# R7FA4L1BD register map
Vendor: Renesas Electronics Corporation; Series: RA4; File version: 0.90.02
CPU: CM33 r0p4, little endian, MPU, FPU, VTOR, 4 interrupt priority bits, 96 interrupts
Registers are 32-bit, read-write, reset 0x0 unless marked. A register's access mark holds for its fields unless they carry their own. Offsets are from the block's base; [hi:lo] are bit positions; {n}, {i} and the like mark numbered series; 'fields as' and 'values as' point back to an identical list; <NAME> marks a mode.

## CTSU — Capacitive Touch Sensing Unit
Base 0x400D0000
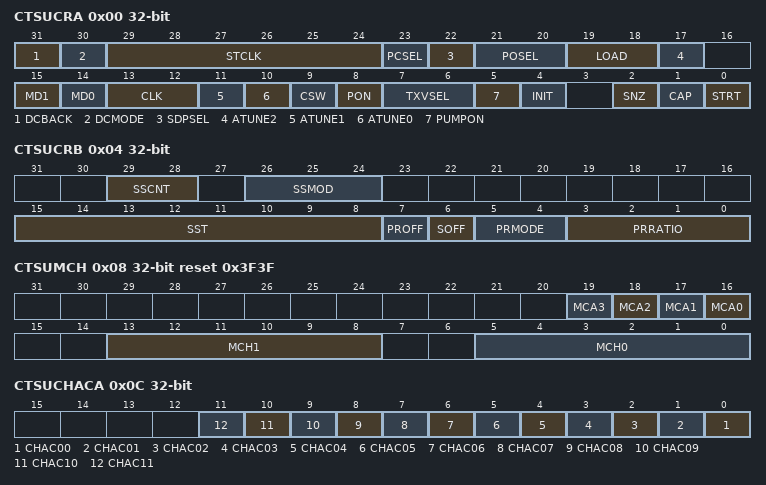
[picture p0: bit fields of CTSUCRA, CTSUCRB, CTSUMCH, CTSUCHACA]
0x00 CTSUCRA — CTSU Control Register A
  [31] DCBACK — CTSU Current Measurement Feedback Select
    0=TSCAP pin is selected; 1=Measurement pin is selected. It is recommended in the current measurement mode.
  [30] DCMODE — CTSU Current Measurement Mode Select
    0=Electrostatic capacitance measurement mode; 1=Current measurement mode
  [29:24] STCLK — CTSU STCLK Select
  [23] PCSEL — CTSU Boost Circuit Clock Select
    0=Sensor drive pulse divided by 2; 1=STCLK
  [22] SDPSEL — CTSU Sensor Drive Pulse Select
    0=Random pulse; 1=Normal pulse using the sensor unit clock
  [21:20] POSEL — CTSU Non-Measured Channel Output Select
    0=Output low; 1=Hi-Z; 2=Output low (uses power supply selected by TXVSEL[1:0] bits); 3=Output a pulse in phase with the transmit channel
  [19:18] LOAD — CTSU Load Control During Measurement
    0=2.5 µA constant current load; 1=No load; 2=20 µA constant current load and overcurrent detector disabled; 3=Resistance load for calibration. To set LOAD[1:0] bits to resistance load for calibration, set these bits to 01b before they are set to 11b.
  [17] ATUNE2 — CTSU Current Range Adjustment
    0=80 µA when ATUNE1 = 0 40 µA when ATUNE1 = 1; 1=20 µA when ATUNE1 = 0 160 µA when ATUNE1 = 1
  [15] MD1 — CTSU Measurement Mode Select 1
    0=One-time measurement (self-capacitance method); 1=Two times measurement (mutual capacitance method)
  [14] MD0 — CTSU Measurement Mode Select 0
    0=Single scan mode; 1=Multi-scan mode
  [13:12] CLK — CTSU Operating Clock Select
    0=PCLKB; 1=PCLKB/2 (PCLKB divided by 2); 2=PCLKB/4 (PCLKB divided by 4); 3=PCLKB/8 (PCLKB divided by 8)
  [11] ATUNE1 — CTSU Current Range Adjustment
    0=80 µA when ATUNE2 = 0 20 µA when ATUNE2 = 1; 1=40 µA when ATUNE2 = 0 160 µA when ATUNE2 = 1
  [10] ATUNE0 — CTSU Power Supply Operating Mode Setting
    0=VCC ≥ 2.4 V: Normal voltage operating mode VCC < 2.4 V: Setting prohibited; 1=Low-voltage operating mode
  [9] CSW — TSCAP Pin Enable
    0=Disable; 1=Enable
  [8] PON — CTSU Power On Control
    0=Power off the CTSU; 1=Power on the CTSU
  [7:6] TXVSEL — CTSU Transmission Power Supply Selection
    0=Selecting VCC as the power supply for the transmit pins of mutual capacitance method; 1=Selecting VCC as the power supply for the transmit pins of the mutual capacitance method. In addition, noise is reduced during GPIO operation. (Recommended); 2=Select VCC as the power source for the transmitter pins used as the active shield; 3=Setting prohibited
  [5] PUMPON — CTSU Boost Circuit Control
    0=Boost circuit off; 1=Boost circuit on
  [4] INIT wo — CTSU Control Block Initialization
  [2] SNZ — CTSU Wait State Power-Saving Enable
    0=Disable power-saving function during wait state; 1=Enable power-saving function during wait state
  [1] CAP — CTSU Measurement Operation Start Trigger Select
    0=Software trigger; 1=External trigger
  [0] STRT — CTSU Measurement Operation Start
    0=Stop measurement operation; 1=Start measurement operation
0x00 CTSUCRAL 16-bit (alternate view of CTSUCRA) — CTSU Control Register A
0x00 CTSUCR0 8-bit (alternate view of CTSUCRA) — CTSU Control Register A
0x01 CTSUCR1 8-bit (alternate view of CTSUCRA) — CTSU Control Register A
0x02 CTSUCR2 8-bit (alternate view of CTSUCRAH) — CTSU Control Register A
0x03 CTSUCR3 8-bit (alternate view of CTSUCRA) — CTSU Control Register A
0x04 CTSUCRB — CTSU Control Register B
  [29:28] SSCNT — SUCLK Spread-Spectrum Control
    0=CTSUTRIMA.SUADJD[7:0] + 0x00; 1=CTSUTRIMA.SUADJD[7:0] + 0x20; 2=CTSUTRIMA.SUADJD[7:0] + 0x40; 3=CTSUTRIMA.SUADJD[7:0] + 0x60
  [26:24] SSMOD — SUCLK Spread-Spectrum Mode Select
    0=256 cycles; 1=384 cycles; 2=512 cycles; 3=1024 cycles; 7=No spread-spectrum; other=Others (Settings are prohibited)
  [15:8] SST — Sensor Stabilization Wait Time Setting
  [7] PROFF — Pseudo-Random Number Off
    0=Perform pseudo-random number control; 1=Do not perform pseudo-random number control
  [6] SOFF — Jitter Injection Off Setting
    0=Inject jitter; 1=Do not inject jitter
  [5:4] PRMODE — Pseudo-Random Number Generation Cycle Setting
    0=255 cycles; 1=63 cycles; 2=31 cycles; 3=3 cycles
  [3:0] PRRATIO — Phase Shift Frequency Setting
0x04 CTSUCRBL 16-bit (alternate view of CTSUCRB) — CTSU Control Register B
0x04 CTSUSDPRS 8-bit (alternate view of CTSUCRB) — CTSU Control Register B
0x05 CTSUSST 8-bit (alternate view of CTSUCRB) — CTSU Control Register B
0x06 CTSUCRBH 16-bit (alternate view of CTSUCRB) — CTSU Control Register B
0x07 CTSUDCLKC 8-bit (alternate view of CTSUCRB) — CTSU Control Register B
0x08 CTSUMCH reset 0x3F3F — CTSU Measurement Channel Register
  [n+16] MCA{n} (n=0..3) — Multiple Clocks Control
    0=Disable; 1=Enable
  [13:8] MCH1 — CTSU Measurement Channel 1
    {v}=TS{v:02} (v=0..11); 63=Measurement is being stopped
  [5:0] MCH0 — CTSU Measurement Channel 0
    {v}=TS{v:02} (v=0..11); 63=Measurement is being stopped
0x08 CTSUMCHL 16-bit reset 0x3F3F (alternate view of CTSUMCH) — CTSU Measurement Channel Register
0x08 CTSUMCH0 8-bit reset 0x3F (alternate view of CTSUMCH) — CTSU Measurement Channel Register
0x09 CTSUMCH1 8-bit reset 0x3F (alternate view of CTSUMCH) — CTSU Measurement Channel Register
0x0A CTSUMCHH 16-bit (alternate view of CTSUMCH) — CTSU Measurement Channel Register
0x0A CTSUMFAF 8-bit (alternate view of CTSUMCHH) — CTSU Measurement Channel Register
0x0C CTSUCHACA — CTSU Channel Enable Control Register A
  [all] fields
    0=Do not measure; 1=Measure
  [n] CHAC{n:02} (n=0..11) — CTSU Channel Enable Control A
0x0C CTSUCHACAL 16-bit (alternate view of CTSUCHACA) — CTSU Channel Enable Control Register A
0x0C CTSUCHAC0 8-bit (alternate view of CTSUCHACA) — CTSU Channel Enable Control Register A
0x0D CTSUCHAC1 8-bit (alternate view of CTSUCHACA) — CTSU Channel Enable Control Register A
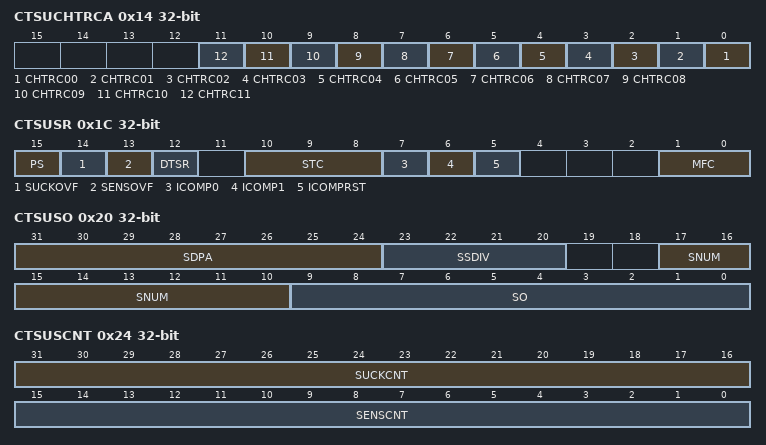
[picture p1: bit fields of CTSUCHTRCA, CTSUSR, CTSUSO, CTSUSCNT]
0x14 CTSUCHTRCA — CTSU Channel Transmit/Receive Control Register A
  [all] fields
    0=Reception; 1=Transmission
  [n] CHTRC{n:02} (n=0..11) — CTSU Channel Transmit/Receive Control A
0x14 CTSUCHTRCAL 16-bit (alternate view of CTSUCHTRCA) — CTSU Channel Transmit/Receive Control Register A
0x14 CTSUCHTRC0 8-bit (alternate view of CTSUCHTRCA) — CTSU Channel Transmit/Receive Control Register A
0x15 CTSUCHTRC1 8-bit (alternate view of CTSUCHTRCA) — CTSU Channel Transmit/Receive Control Register A
0x1C CTSUSR — CTSU Status Register
  [15] PS ro — CTSU Mutual Capacitance Status Flag
    0=First measurement; 1=Second measurement
  [14] SUCKOVF — CTSU SUCLK Counter Overflow Flag
    0=No overflow occurred; 1=Overflow occurred
  [13] SENSOVF — CTSU Sensor Counter Overflow Flag
    0=No overflow occurred; 1=Overflow occurred
  [12] DTSR ro — CTSU Data Transfer Status Flag
    0=Read; 1=Not read
  [10:8] STC ro — CTSU Measurement Status Counter
    {v}=Status {v} (v=0..5)
  [7] ICOMP0 ro — Over-Voltage Detection Flag
    0=Normal; 1=Over-voltage is detected
  [6] ICOMP1 ro — CTSU Sense Current Error Monitor
    0=Normal sensor current; 1=Abnormal sensor current
  [5] ICOMPRST wo — CTSU ICOMP0 and ICOMP1 Flags Reset
  [1:0] MFC — CTSU Multi-Clock Counter
    {v}=Multi-clock {v} (v=0..3)
0x1C CTSUSRL 16-bit (alternate view of CTSUSR) — CTSU Status Register
0x1C CTSUSR0 8-bit (alternate view of CTSUSR) — CTSU Status Register
0x1D CTSUST 8-bit (alternate view of CTSUSR) — CTSU Status Register
0x1E CTSUSRH 16-bit (alternate view of CTSUSR) — CTSU Status Register
0x1E CTSUSR2 8-bit (alternate view of CTSUSRH) — CTSU Status Register
0x20 CTSUSO — CTSU Sensor Offset Register
  [31:24] SDPA — CTSU Base Clock Setting
  [23:20] SSDIV — Spread Spectrum Frequency
  [17:10] SNUM — CTSU Measurement Count Setting
  [9:0] SO — CTSU Sensor Offset Adjustment
0x20 CTSUSO0 16-bit (alternate view of CTSUSO) — CTSU Sensor Offset Register
0x22 CTSUSO1 16-bit (alternate view of CTSUSO) — CTSU Sensor Offset Register
0x24 CTSUSCNT ro — CTSU Sensor Counter Register
  [31:16] SUCKCNT — CTSU SUCLK Counter
  [15:0] SENSCNT — CTSU Sensor Counter
0x24 CTSUSC 16-bit ro (alternate view of CTSUSCNT) — CTSU Sensor Counter Register
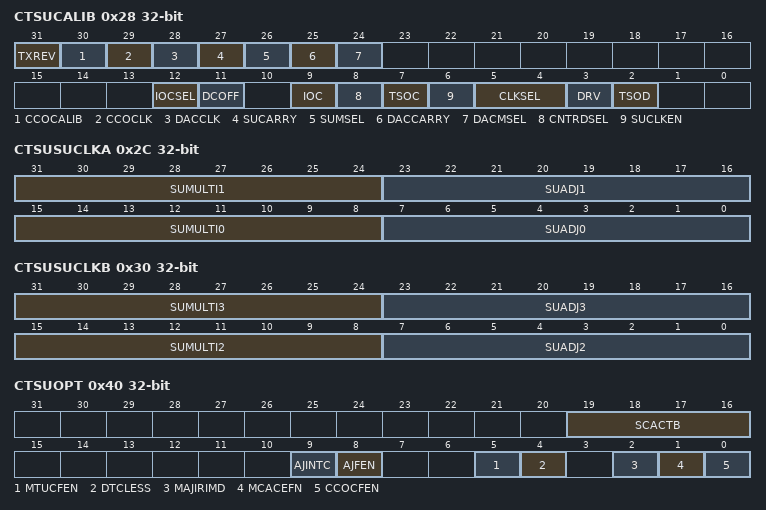
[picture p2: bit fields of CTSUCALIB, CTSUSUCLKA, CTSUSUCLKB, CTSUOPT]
0x28 CTSUCALIB — CTSU Calibration Register
  [31] TXREV — Transmit Pin Inverted Output
    0=Normal; 1=Invert
  [30] CCOCALIB — Calibration Selection of Current Controlled Oscillator for Measurement
    0=Capacitance measurement mode; 1=Oscillator calibration mode
  [29] CCOCLK — Modulation Clock Select for Current Controlled Oscillator Input Current of SUCLK
    0=Operating clock selected by CTSUCRA.CLK [1:0]; 1=SUCLK
  [28] DACCLK — Modulation Clock Select for Offset Current Circuits
    0=Operating clock selected by CTSUCRA.CLK [1:0]; 1=SUCLK
  [27] SUCARRY — Current Control Oscillator Input Current Adjustment for SUCLK
    0=Normal operation; 1=All current sources can be turned on
  [26] SUMSEL — Current Control Oscillator Input Current Matrix Calibration Select
    0=Capacitance measurement mode; 1=Current control oscillator input current matrix calibration mode
  [25] DACCARRY — Offset Current Adjustment for Calibration
    0=Normal operation; 1=All current sources can be turned on
  [24] DACMSEL — Current Offset DAC Current Matrix Calibration Select
    0=Capacitance measurement mode; 1=Current offset DAC current Calibration mode
  [12] IOCSEL — TS Pins Fixed Output Select
    0=Sensor drive pulse; 1=The level selected by the IOC bit is output
  [11] DCOFF — Down Converter Control
    0=Voltage down converter operation (TSCAP voltage generation); 1=The voltage down converter is off
  [9] IOC — Transmit Pin Control
  [8] CNTRDSEL — Read Count Select of Sensor Counter
    0=Read once; 1=Read twice
  [7] TSOC — Switched Capacitor Operation Calibration Select Bit
    0=Capacitance measurement mode; 1=Switched capacitor operation calibration mode
  [6] SUCLKEN — SUCLK Forced Oscillation Control
    0=SUCLK oscillation only during measurement; 1=SUCLK always oscillates
  [5:4] CLKSEL — Observation Clock Select
    0=Not selected (L fixed output); 1=Measurement clock (divided by 8); 2=Setting prohibited; 3=SUCLK (divided by 8)
  [3] DRV — Power Supply Calibration Select
    0=Capacitance measurement mode; 1=Power supply calibration mode
  [2] TSOD — All TS Pin Output Control
    0=Does not output from TS terminals; 1=All TS terminals output (controlled by the IOCSEL bit)
0x28 CTSUDBGR0 16-bit (alternate view of CTSUCALIB) — CTSU Calibration Register
0x2A CTSUDBGR1 16-bit (alternate view of CTSUCALIB) — CTSU Calibration Register
0x2C CTSUSUCLKA — CTSU Sensor Unit Clock Control Register A
  [31:24] SUMULTI1 — CTSU SUCLK Multiplier Rate Setting
  [23:16] SUADJ1 — CTSU SUCLK Frequency Adjustment
  [15:8] SUMULTI0 — CTSU SUCLK Multiplier Rate Setting
  [7:0] SUADJ0 — CTSU SUCLK Frequency Adjustment
0x2C CTSUSUCLK0 16-bit (alternate view of CTSUSUCLKA) — CTSU Sensor Unit Clock Control Register A
0x2E CTSUSUCLK1 16-bit (alternate view of CTSUSUCLKA) — CTSU Sensor Unit Clock Control Register A
0x30 CTSUSUCLKB — CTSU Sensor Unit Clock Control Register B
  [31:24] SUMULTI3 — CTSU SUCLK Multiplier Rate Setting
  [23:16] SUADJ3 — CTSU SUCLK Frequency Adjustment
  [15:8] SUMULTI2 — CTSU SUCLK Multiplier Rate Setting
  [7:0] SUADJ2 — CTSU SUCLK Frequency Adjustment
0x30 CTSUSUCLK2 16-bit (alternate view of CTSUSUCLKB) — CTSU Sensor Unit Clock Control Register B
0x32 CTSUSUCLK3 16-bit (alternate view of CTSUSUCLKB) — CTSU Sensor Unit Clock Control Register B
0x40 CTSUOPT — CTSU Option Setting Register
  [19:16] SCACTB — Sensor Counter Automatic Correction Table Number Setting
  [9] AJINTC — Automatic Judgment Interrupt Control
    0=INTFN_N for touch detection, INTAJN_N for non-touch detection; 1=INTFN_N only regardless of touch/non-touch detection
  [8] AJFEN — Automatic Judgment Function Enable
    0=Automatic judgment function is disabled; 1=Automatic judgment function is enabled
  [5] MTUCFEN — Mutual Capacitance Calculation Enable
    0=Do not subtract the first measurement data from the second measurement data; 1=Subtract the first measurement data from the second measurement data
  [4] DTCLESS — Data Transfer Request Disable
    0=Data transfer request is enabled; 1=Data transfer request is disabled
  [2] MAJIRIMD — Majority Mode
    0=Majority mode is not used; 1=Majority mode is used
  [1] MCACEFN — Multi-clock Correction Function Enable
    0=Multi-clock correction function is disabled; 1=Multi-clock correction function is enabled
  [0] CCOCFEN — CCO Characteristics Correction Function Enable
    0=CCO characteristics correction function is disabled; 1=CCO characteristics correction function is enabled
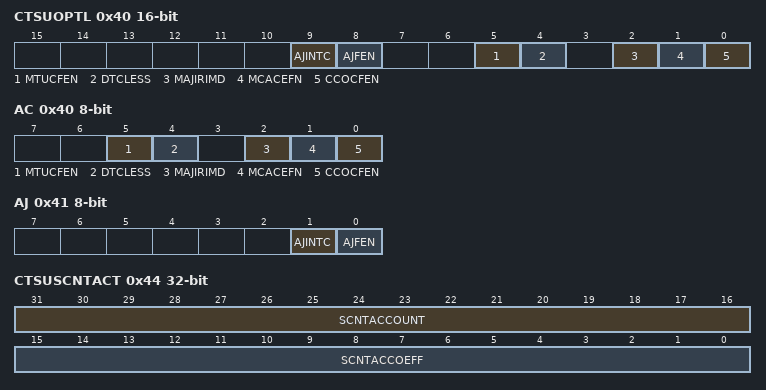
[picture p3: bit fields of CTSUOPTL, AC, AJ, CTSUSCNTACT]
0x40 CTSUOPTL 16-bit (alternate view of CTSUOPT) — CTSU Option Setting Register
  [9] AJINTC — Automatic Judgment Interrupt Control
    values as CTSUOPT.AJINTC
  [8] AJFEN — Automatic Judgment Function Enable
    values as CTSUOPT.AJFEN
  [5] MTUCFEN — Mutual Capacitance Calculation Enable
    values as CTSUOPT.MTUCFEN
  [4] DTCLESS — Data Transfer Request Disable
    values as CTSUOPT.DTCLESS
  [2] MAJIRIMD — Majority Mode
    0=Majority mode is not used; 1=Majority mode is used
  [1] MCACEFN — Multi-clock Correction Function Enable
    values as CTSUOPT.MCACEFN
  [0] CCOCFEN — CCO Characteristics Correction Function Enable
    values as CTSUOPT.CCOCFEN
0x40 AC 8-bit (alternate view of CTSUOPT) — CTSU Option Setting Register
  [5] MTUCFEN — Mutual Capacitance Calculation Enable
    values as CTSUOPT.MTUCFEN
  [4] DTCLESS — Data Transfer Request Disable
    values as CTSUOPT.DTCLESS
  [2] MAJIRIMD — Majority Mode
    0=Majority mode is not used; 1=Majority mode is used
  [1] MCACEFN — Multi-clock Correction Function Enable
    values as CTSUOPT.MCACEFN
  [0] CCOCFEN — CCO Characteristics Correction Function Enable
    values as CTSUOPT.CCOCFEN
0x41 AJ 8-bit (alternate view of CTSUOPT) — CTSU Option Setting Register
  [1] AJINTC — Automatic Judgment Interrupt Control
    values as CTSUOPT.AJINTC
  [0] AJFEN — Automatic Judgment Function Enable
    values as CTSUOPT.AJFEN
0x42 CTSUOPTH 16-bit (alternate view of CTSUOPT) — CTSU Option Setting Register
  [3:0] SCACTB — Sensor Counter Automatic Correction Table Number Setting
0x42 ACSB 8-bit (alternate view of CTSUOPTH) — CTSU Option Setting Register
  fields as CTSUOPTH
0x44 CTSUSCNTACT — CTSU Sensor Counter Automatic Correction Table Access Register
  [31:16] SCNTACCOUNT — Set the measurement value to be compared.
  [15:0] SCNTACCOEFF — Sensor Counter Correction Coefficient Setting
0x44 CTSUSCNTACTL 16-bit (alternate view of CTSUSCNTACT) — CTSU Sensor Counter Automatic Correction Table Access Register
  [15:0] SCNTACCOEFF — Sensor Counter Correction Coefficient Setting
0x46 CTSUSCNTACTH 16-bit (alternate view of CTSUSCNTACT) — CTSU Sensor Counter Automatic Correction Table Access Register
  [15:0] SCNTACCOUNT — Set the measurement value to be compared.
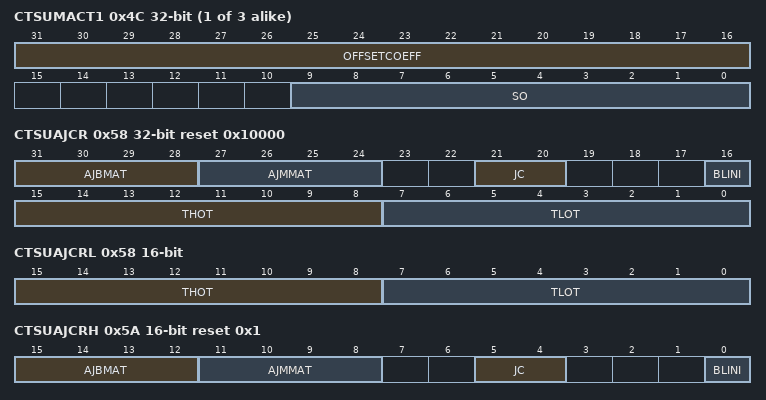
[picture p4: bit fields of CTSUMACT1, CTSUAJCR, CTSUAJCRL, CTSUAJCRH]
{0x48+4i} CTSUMACT{i} (i=1..3) — CTSU Multi-Clock Automatic Correction Table Access Register
  [31:16] OFFSETCOEFF — Offset coefficient bits for multi-clock
  [9:0] SO — Sensor offset adjustment bits for multi-clock
{0x48+4i} CTSUMACT{i}L 16-bit (alternate view of CTSUMACT{i}) (i=1..3) — CTSU Multi-Clock Automatic Correction Table Access Register
  [9:0] SO — Sensor offset adjustment bits for multi-clock
{0x4A+4i} CTSUMACT{i}H 16-bit (alternate view of CTSUMACT{i}) (i=1..3) — CTSU Multi-Clock Automatic Correction Table Access Register
  [15:0] OFFSETCOEFF — Offset coefficient bits for multi-clock
0x58 CTSUAJCR reset 0x10000 — CTSU Automatic Judgment Control Register
  [31:28] AJBMAT — Baseline Average Number Setting
  [27:24] AJMMAT — Measured Value Moving Average Number Setting
  [21:20] JC — Judgment Condition Setting
    0=Judges as touch when there is one or more touch detections; 1=Judges as touch when there are two or more touch detections; 2=Judges as touch when there are three or more touch detections; 3=Judges as touch only when there are four touch detections
  [16] BLINI — Baseline Initialization
    0=Perform baseline operations; 1=Initialize the results of baseline operations
  [15:8] THOT — Touch Judgment Criterion Setting
  [7:0] TLOT — Non-Touch Judgment Criterion Setting
0x58 CTSUAJCRL 16-bit (alternate view of CTSUAJCR) — CTSU Automatic Judgment Control Register
  [15:8] THOT — Touch Judgment Criterion Setting
  [7:0] TLOT — Non-Touch Judgment Criterion Setting
0x58 AJCR0 8-bit (alternate view of CTSUAJCR) — CTSU Automatic Judgment Control Register
  [7:0] TLOT — Non-Touch Judgment Criterion Setting
0x59 AJCR1 8-bit (alternate view of CTSUAJCR) — CTSU Automatic Judgment Control Register
  [7:0] THOT — Touch Judgment Criterion Setting
0x5A CTSUAJCRH 16-bit reset 0x1 (alternate view of CTSUAJCR) — CTSU Automatic Judgment Control Register
  [15:12] AJBMAT — Baseline Average Number Setting
  [11:8] AJMMAT — Measured Value Moving Average Number Setting
  [5:4] JC — Judgment Condition Setting
    values as CTSUAJCR.JC
  [0] BLINI — Baseline Initialization
    values as CTSUAJCR.BLINI
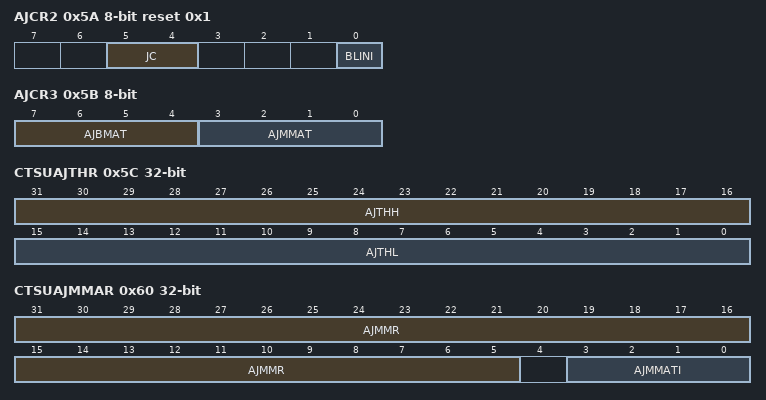
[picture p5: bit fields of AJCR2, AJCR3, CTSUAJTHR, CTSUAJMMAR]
0x5A AJCR2 8-bit reset 0x1 (alternate view of CTSUAJCRH) — CTSU Automatic Judgment Control Register
  [5:4] JC — Judgment Condition Setting
    values as CTSUAJCR.JC
  [0] BLINI — Baseline Initialization
    values as CTSUAJCR.BLINI
0x5B AJCR3 8-bit (alternate view of CTSUAJCR) — CTSU Automatic Judgment Control Register
  [7:4] AJBMAT — Baseline Average Number Setting
  [3:0] AJMMAT — Measured Value Moving Average Number Setting
0x5C CTSUAJTHR — CTSU Automatic Judgment Control Register
  [31:16] AJTHH — Upper Threshold Setting
  [15:0] AJTHL — Lower Threshold Setting
0x5C CTSUAJTHRL 16-bit (alternate view of CTSUAJTHR) — CTSU Automatic Judgment Control Register
  [15:0] AJTHL — Lower Threshold Setting
0x5E CTSUAJTHRH 16-bit (alternate view of CTSUAJTHR) — CTSU Automatic Judgment Control Register
  [15:0] AJTHH — Upper Threshold Setting
0x60 CTSUAJMMAR — CTSU Threshold Register
  [31:5] AJMMR — Moving Average Result
  [3:0] AJMMATI — Moving Average Count
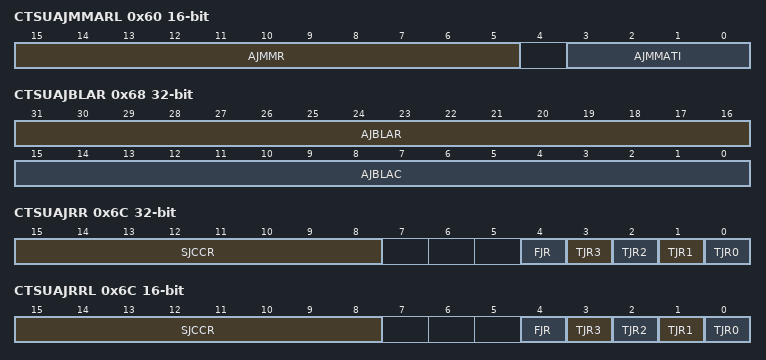
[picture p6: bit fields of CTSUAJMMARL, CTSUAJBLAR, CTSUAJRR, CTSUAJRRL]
0x60 CTSUAJMMARL 16-bit (alternate view of CTSUAJMMAR) — CTSU Threshold Register
  [15:5] AJMMR — Moving Average Result
  [3:0] AJMMATI — Moving Average Count
0x62 CTSUAJMMARH 16-bit (alternate view of CTSUAJMMAR) — CTSU Threshold Register
  [15:0] AJMMR — Moving Average Result
0x64 CTSUAJBLACT — CTSU Baseline Average Intermediate Result Register
  [31:0] AJBLACT — Automatic determination baseline average calculation bits
0x64 CTSUAJBLACTL 16-bit (alternate view of CTSUAJBLACT) — CTSU Baseline Average Intermediate Result Register
  [15:0] AJBLACT — Automatic determination baseline average calculation bits
0x66 CTSUAJBLACTH 16-bit (alternate view of CTSUAJBLACT) — CTSU Baseline Average Intermediate Result Register
  fields as CTSUAJBLACTL
0x68 CTSUAJBLAR — CTSU Baseline Average Result Register
  [31:16] AJBLAR — Baseline Average Result
  [15:0] AJBLAC — Baseline Average Count
0x68 CTSUAJBLARL 16-bit (alternate view of CTSUAJBLAR) — CTSU Baseline Average Result Register
  [15:0] AJBLAC — Baseline Average Count
0x6A CTSUAJBLARH 16-bit (alternate view of CTSUAJBLAR) — CTSU Baseline Average Result Register
  [15:0] AJBLAR — Baseline Average Result
0x6C CTSUAJRR — CTSU Automatic Judgment Result Register
  [15:8] SJCCR — Remaining Number of Consecutive Detections
  [4] FJR — The final judgment result on multi-clock measurement is stored. If multi-clock measurement is not specified, the same value as the TJR0 flag is stored.
    0=Non-touch; 1=Touch
  [3] TJR3 — The judgment result when using SUCLK3 is stored.
    0=Non-touch; 1=Touch
  [2] TJR2 — The judgment result when using SUCLK2 is stored.
    0=Non-touch; 1=Touch
  [1] TJR1 — The judgment result when using SUCLK1 is stored.
    0=Non-touch; 1=Touch
  [0] TJR0 — The judgment result when using random pulse or SUCLK0 is stored.
    0=Non-touch; 1=Touch
0x6C CTSUAJRRL 16-bit (alternate view of CTSUAJRR) — CTSU Automatic Judgment Result Register
  fields as CTSUAJRR
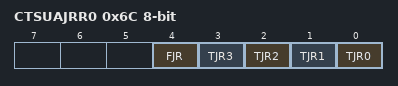
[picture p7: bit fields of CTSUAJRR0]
0x6C CTSUAJRR0 8-bit (alternate view of CTSUAJRR) — CTSU Automatic Judgment Result Register
  [all] fields
    0=Non-touch; 1=Touch
  [4] FJR — The final judgment result on multi-clock measurement is stored. If multi-clock measurement is not specified, the same value as the TJR0 flag is stored.
  [3] TJR3 — The judgment result when using SUCLK3 is stored.
  [2] TJR2 — The judgment result when using SUCLK2 is stored.
  [1] TJR1 — The judgment result when using SUCLK1 is stored.
  [0] TJR0 — The judgment result when using random pulse or SUCLK0 is stored.
0x6D CTSUAJRR1 8-bit (alternate view of CTSUAJRR) — CTSU Automatic Judgment Result Register
  [7:0] SJCCR — Remaining Number of Consecutive Detections
